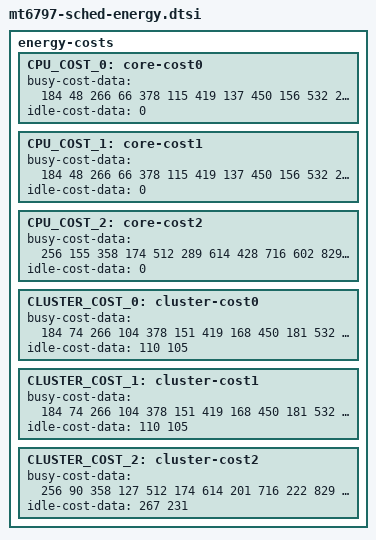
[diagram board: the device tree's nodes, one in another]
energy-costs {
	CPU_COST_0: core-cost0 {
		busy-cost-data = <
			184    48
			266    66
			378   115
			419   137
			450   156
			532   217
			573   251
			593   273
		>;
		idle-cost-data = <
			  0
		>;
	};
	CPU_COST_1: core-cost1 {
		busy-cost-data = <
			184    48
			266    66
			378   115
			419   137
			450   156
			532   217
			573   251
			593   273
		>;
		idle-cost-data = <
			  0
		>;
	};
	CPU_COST_2: core-cost2 {
		busy-cost-data = <
			256   155
			358   174
			512   289
			614   428
			716   602
			829   835
			921  1098
			1024  1382
		>;
		idle-cost-data = <
			  0
		>;
	};
	CLUSTER_COST_0: cluster-cost0 {
		busy-cost-data = <
			184    74
			266   104
			378   151
			419   168
			450   181
			532   220
			573   238
			593   250
		>;
		idle-cost-data = <
			 110
			 105
		>;
	};
	CLUSTER_COST_1: cluster-cost1 {
		busy-cost-data = <
			184    74
			266   104
			378   151
			419   168
			450   181
			532   220
			573   238
			593   250
		>;
		idle-cost-data = <
			 110
			 105
		>;
	};
	CLUSTER_COST_2: cluster-cost2 {
		busy-cost-data = <
			256    90
			358   127
			512   174
			614   201
			716   222
			829   240
			921   252
			1024   259
		>;
		idle-cost-data = <
			267
			231
		>;
	};
};
